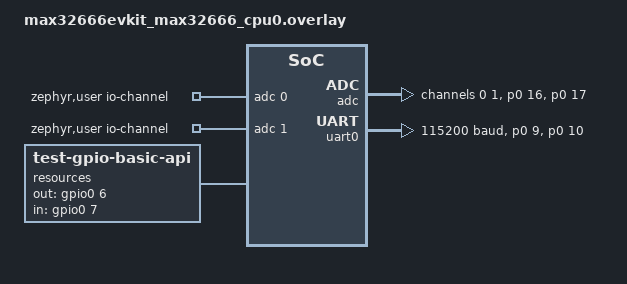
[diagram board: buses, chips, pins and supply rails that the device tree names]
/*
 * Copyright (c) 2025 Analog Devices, Inc.
 *
 * SPDX-License-Identifier: Apache-2.0
 */

tst_dma0: &dma0 {};

/ {
	zephyr,user {
		io-channels = <&adc 0>, <&adc 1>;
	};
};

&adc {
	status = "okay";
	pinctrl-0 = <&ain0n_p0_16 &ain0p_p0_17>;
	pinctrl-names = "default";
	#address-cells = <1>;
	#size-cells = <0>;
	channel@0 {
		reg = <0>;
		zephyr,gain = "ADC_GAIN_1";
		zephyr,reference = "ADC_REF_INTERNAL";
		zephyr,acquisition-time = <ADC_ACQ_TIME_DEFAULT>;
		zephyr,resolution = <10>;
	};
	channel@1 {
		reg = <1>;
		zephyr,gain = "ADC_GAIN_1";
		zephyr,reference = "ADC_REF_INTERNAL";
		zephyr,acquisition-time = <ADC_ACQ_TIME_DEFAULT>;
		zephyr,resolution = <10>;
	};
};

/ {
	resources {
		compatible = "test-gpio-basic-api";
		out-gpios = <&gpio0 6 0>;
		in-gpios = <&gpio0 7 0>;
	};
};

dut: &uart0 {
	status = "okay";
	pinctrl-0 = <&uart0_tx_p0_9 &uart0_rx_p0_10>;
	pinctrl-names = "default";
	dmas = <&dma0 1 MAX32_DMA_SLOT_UART0_TX>, <&dma0 2 MAX32_DMA_SLOT_UART0_RX>;
	dma-names = "tx", "rx";
	current-speed = <115200>;
	data-bits = <8>;
	parity = "none";
};
